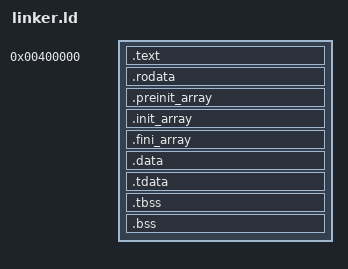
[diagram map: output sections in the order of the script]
OUTPUT_FORMAT("elf64-x86-64")
OUTPUT_ARCH(i386:x86-64)
ENTRY(_start)

PHDRS
{
    text PT_LOAD FLAGS(5);
    rodata PT_LOAD FLAGS(4);
    data PT_LOAD FLAGS(6);
}

SECTIONS
{
    . = 0x400000;

    .text : ALIGN(4K) {
        KEEP(*(.text._start))
        *(.text .text.*)
    } :text

    .rodata : ALIGN(4K) {
        *(.rodata .rodata.*)
        *(.eh_frame_hdr)
        *(.eh_frame)
    } :rodata

    .preinit_array : ALIGN(8) {
        PROVIDE_HIDDEN(__preinit_array_start = .);
        KEEP(*(.preinit_array))
        PROVIDE_HIDDEN(__preinit_array_end = .);
    } :rodata

    .init_array : ALIGN(8) {
        PROVIDE_HIDDEN(__init_array_start = .);
        KEEP(*(SORT_BY_INIT_PRIORITY(.init_array.*) SORT_BY_INIT_PRIORITY(.ctors.*)))
        KEEP(*(.init_array EXCLUDE_FILE(*crtend*.o *crtbegin*.o) .ctors))
        PROVIDE_HIDDEN(__init_array_end = .);
    } :rodata

    .fini_array : ALIGN(8) {
        PROVIDE_HIDDEN(__fini_array_start = .);
        KEEP(*(SORT_BY_INIT_PRIORITY(.fini_array.*) SORT_BY_INIT_PRIORITY(.dtors.*)))
        KEEP(*(.fini_array EXCLUDE_FILE(*crtend*.o *crtbegin*.o) .dtors))
        PROVIDE_HIDDEN(__fini_array_end = .);
    } :rodata

    .data : ALIGN(4K) {
        *(.data .data.*)
    } :data

    .tdata : ALIGN(16) {
        *(.tdata .tdata.*)
    } :data

    .tbss : ALIGN(16) {
        *(.tbss .tbss.*)
    } :data

    .bss : ALIGN(4K) {
        *(COMMON)
        *(.bss .bss.*)
    } :data

    _end = .;

    /DISCARD/ : {
        *(.comment)
        *(.note*)
    }
}
